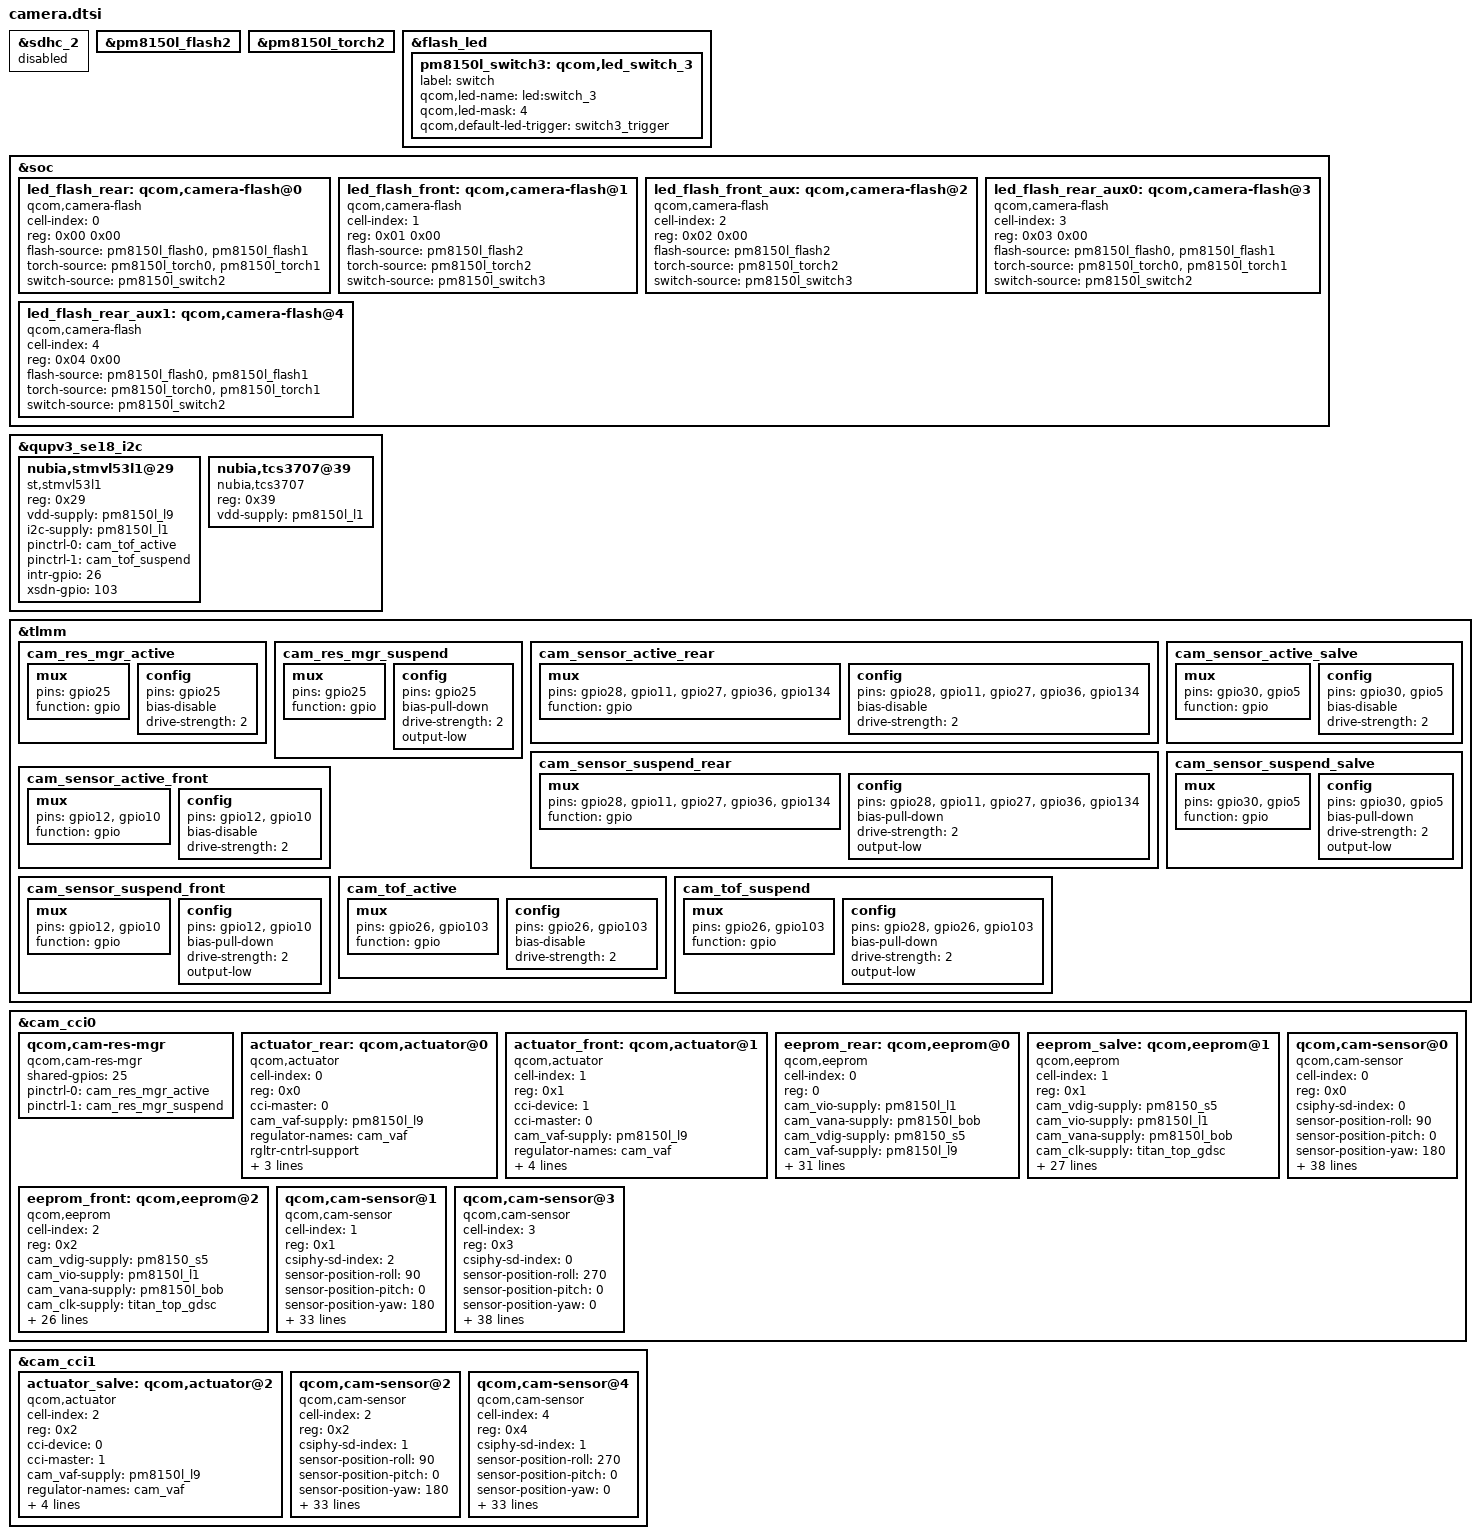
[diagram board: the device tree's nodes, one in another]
/*
 * Copyright (c) 2018, The Linux Foundation. All rights reserved.
 *
 * This program is free software; you can redistribute it and/or modify
 * it under the terms of the GNU General Public License version 2 and
 * only version 2 as published by the Free Software Foundation.
 *
 * This program is distributed in the hope that it will be useful,
 * but WITHOUT ANY WARRANTY; without even the implied warranty of
 * MERCHANTABILITY or FITNESS FOR A PARTICULAR PURPOSE.  See the
 * GNU General Public License for more details.
 */




&sdhc_2 {
	status = "disabled";
};
&pm8150l_flash2 {
    status = "ok";
};
&pm8150l_torch2 {
     status = "ok";
};
&flash_led {

	pm8150l_switch3: qcom,led_switch_3 {
		label = "switch";
		qcom,led-name = "led:switch_3";
		qcom,led-mask = <4>;
		qcom,default-led-trigger = "switch3_trigger";
	};
};
&soc {



	led_flash_rear: qcom,camera-flash@0 {
		cell-index = <0>;
		reg = <0x00 0x00>;
		compatible = "qcom,camera-flash";
		flash-source = <&pm8150l_flash0 &pm8150l_flash1>;
		torch-source = <&pm8150l_torch0 &pm8150l_torch1>;
		switch-source = <&pm8150l_switch2>;
		status = "ok";
	};
	led_flash_front: qcom,camera-flash@1 {
		cell-index = <1>;
		reg = <0x01 0x00>;
		compatible = "qcom,camera-flash";
		flash-source = <&pm8150l_flash2>;
		torch-source = <&pm8150l_torch2>;
		switch-source = <&pm8150l_switch3>;
		status = "ok";
	};
	led_flash_front_aux: qcom,camera-flash@2 {
		cell-index = <2>;
		reg = <0x02 0x00>;
		compatible = "qcom,camera-flash";
		flash-source = <&pm8150l_flash2>;
		torch-source = <&pm8150l_torch2>;
		switch-source = <&pm8150l_switch3>;
		status = "ok";
	};

	led_flash_rear_aux0: qcom,camera-flash@3 {
		cell-index = <3>;
		reg = <0x03 0x00>;
		compatible = "qcom,camera-flash";
		flash-source = <&pm8150l_flash0 &pm8150l_flash1>;
		torch-source = <&pm8150l_torch0 &pm8150l_torch1>;
		switch-source = <&pm8150l_switch2>;
		status = "ok";
	};

	led_flash_rear_aux1: qcom,camera-flash@4 {
		cell-index = <4>;
		reg = <0x04 0x00>;
		compatible = "qcom,camera-flash";
		flash-source = <&pm8150l_flash0 &pm8150l_flash1>;
		torch-source = <&pm8150l_torch0 &pm8150l_torch1>;
		switch-source = <&pm8150l_switch2>;
		status = "ok";
	};

};
	
&qupv3_se18_i2c {
        status = "ok";
	nubia,stmvl53l1@29 {
	        status = "okay";
		compatible = "st,stmvl53l1";
		reg = <0x29>;
		vdd-supply = <&pm8150l_l9>;
		i2c-supply = <&pm8150l_l1>;
		//interrupt-parent = <&tlmm>;
		//interrupts = <26 0x00>;
		pinctrl-names = "pmx_ts_active","pmx_ts_suspend";
		pinctrl-0 = <&cam_tof_active>;
		pinctrl-1 = <&cam_tof_suspend>;		
		intr-gpio = <26>;
		xsdn-gpio = <103>;
	};
	nubia,tcs3707@39{
		status = "okay";
		compatible = "nubia,tcs3707";
		reg = <0x39>;
		vdd-supply = <&pm8150l_l1>;
	};
};

&tlmm {
	/delete-node/ cam_sensor_front_active;
	/delete-node/ cam_sensor_front_suspend;
	/delete-node/ cam_sensor_rear_active;
	/delete-node/ cam_sensor_rear_suspend;

	cam_res_mgr_active: cam_res_mgr_active {
		/* AVDD_LDO*/
		mux {
			pins = "gpio25";
			function = "gpio";
		};

		config {
			pins = "gpio25";
			bias-disable; /* No PULL */
			drive-strength = <2>; /* 2 MA */
		};
	};

	cam_res_mgr_suspend: cam_res_mgr_suspend {
		/* AVDD_LDO */
		mux {
			pins = "gpio25";
			function = "gpio";
		};

		config {
			pins = "gpio25";
			bias-pull-down; /* PULL DOWN */
			drive-strength = <2>; /* 2 MA */
			output-low;
		};
	};

	cam_sensor_active_rear: cam_sensor_active_rear {
		/* RESET REAR */
		mux {
			pins = "gpio28", "gpio11", "gpio27", "gpio36","gpio134";
			function = "gpio";
		};

		config {
			pins = "gpio28", "gpio11", "gpio27", "gpio36","gpio134";
			bias-disable; /* No PULL */
			drive-strength = <2>; /* 2 MA */
		};
	};

	cam_sensor_suspend_rear: cam_sensor_suspend_rear {
		/* RESET REAR */
		mux {
			pins = "gpio28", "gpio11", "gpio27", "gpio36","gpio134";
			function = "gpio";
		};

		config {
			pins = "gpio28", "gpio11", "gpio27", "gpio36","gpio134";
			bias-pull-down; /* PULL DOWN */
			drive-strength = <2>; /* 2 MA */
			output-low;
		};
	};


	cam_sensor_active_front: cam_sensor_active_front {
		/* RESET FRONT */
		mux {
			pins = "gpio12", "gpio10";
			function = "gpio";
		};

		config {
			pins = "gpio12", "gpio10";
			bias-disable; /* No PULL */
			drive-strength = <2>; /* 2 MA */
		};
	};

	cam_sensor_suspend_front: cam_sensor_suspend_front {
		/* RESET FRONT */
		mux {
			pins = "gpio12", "gpio10";
			function = "gpio";
		};

		config {
			pins = "gpio12", "gpio10";
			bias-pull-down; /* PULL DOWN */
			drive-strength = <2>; /* 2 MA */
			output-low;
		};
	};
	cam_sensor_active_salve: cam_sensor_active_salve {
		/* RESET SALVE */
		mux {
			pins = "gpio30", "gpio5";
			function = "gpio";
		};

		config {
			pins = "gpio30", "gpio5";
			bias-disable; /* No PULL */
			drive-strength = <2>; /* 2 MA */
		};
	};

	cam_sensor_suspend_salve: cam_sensor_suspend_salve {
		/* RESET SALVE */
		mux {
			pins = "gpio30", "gpio5";
			function = "gpio";
		};

		config {
			pins = "gpio30", "gpio5";
			bias-pull-down; /* PULL DOWN */
			drive-strength = <2>; /* 2 MA */
			output-low;
		};
	};	

	cam_tof_active: cam_tof_active {
		/* TOF */
		mux {
			pins = "gpio26", "gpio103";
			function = "gpio";
		};

		config {
			pins = "gpio26", "gpio103";
			bias-disable; /* No PULL */
			drive-strength = <2>; /* 2 MA */
		};
	};

	cam_tof_suspend: cam_tof_suspend {
		/* TOF */
		mux {
			pins = "gpio26", "gpio103";
			function = "gpio";
		};

		config {
			pins = "gpio28", "gpio26", "gpio103";
			bias-pull-down; /* PULL DOWN */
			drive-strength = <2>; /* 2 MA */
			output-low;
		};
	};


};
&cam_cci0 {

	qcom,cam-res-mgr {
		compatible = "qcom,cam-res-mgr";
		status = "ok";
		shared-gpios = <25>;
		pinctrl-names = "cam_res_mgr_default", "cam_res_mgr_suspend";
		pinctrl-0 = <&cam_res_mgr_active>;
		pinctrl-1 = <&cam_res_mgr_suspend>;
	};

#if 0
	tcs37070: nubia,tcs3707@0{
		cell-index = <0>;
		reg = <0x39>;
		compatible = "nubia,tcs3707";
		cci-master = <0>;
		cci-device = <0>;
		vdd-supply = <&pm8150l_l1>;
	};	

	tof0: nubia,tof@0{
		cell-index = <0>;
		reg = <0x29>;
		compatible = "st,stmvl53l1";
		cci-master = <0>;
		cci-device = <0>;
		laser-supply = <&pm8150l_l9>;
		cci-supply = <&pm8150l_l1>;
		pinctrl-names = "cam_default", "cam_suspend";
		pinctrl-0 = <&cam_tof_active>;
		pinctrl-1 = <&cam_tof_suspend>;
		intr-gpio = <26>;
		xsdn-gpio = <103>;
	};	
#endif

	actuator_rear: qcom,actuator@0 {
		cell-index = <0>;
		reg = <0x0>;
		compatible = "qcom,actuator";
		cci-master = <0>;
		cam_vaf-supply = <&pm8150l_l9>;
		regulator-names = "cam_vaf";
		rgltr-cntrl-support;
		rgltr-min-voltage = <2800000>;
		rgltr-max-voltage = <2800000>;
		rgltr-load-current = <1200000>;
	};

	actuator_front: qcom,actuator@1 {
		cell-index = <1>;
		reg = <0x1>;
		compatible = "qcom,actuator";
		cci-device = <1>;
		cci-master = <0>;
		cam_vaf-supply = <&pm8150l_l9>;
		regulator-names = "cam_vaf";
		rgltr-cntrl-support;
		rgltr-min-voltage = <2800000>;
		rgltr-max-voltage = <2800000>;
		rgltr-load-current = <1200000>;
	};
	eeprom_rear: qcom,eeprom@0 {
		cell-index = <0>;
		reg = <0>;
		compatible = "qcom,eeprom";
		cam_vio-supply = <&pm8150l_l1>;
		cam_vana-supply = <&pm8150l_bob>;
		cam_vdig-supply = <&pm8150_s5>;
		cam_vaf-supply = <&pm8150l_l9>;
		cam_clk-supply = <&titan_top_gdsc>;
		regulator-names = "cam_vio", "cam_vana", "cam_vdig", "cam_vaf",
			"cam_clk";
		rgltr-cntrl-support;
		rgltr-min-voltage = <0 3300000 1950000 2800000 0>;
		rgltr-max-voltage = <0 3300000 1950000 2800000 0>;
		rgltr-load-current = <0 80000 1200000 1200000 0>;
		gpio-no-mux = <0>;
		pinctrl-names = "cam_default", "cam_suspend";
		pinctrl-0 = <&cam_sensor_mclk0_active
				&cam_sensor_active_rear>;
		pinctrl-1 = <&cam_sensor_mclk0_suspend
				&cam_sensor_suspend_rear>;
		gpios = <&tlmm 13 0>,
			<&tlmm 28 0>,
			<&tlmm 11 0>,
			<&tlmm 27 0>,
			<&tlmm 134 0>,
			<&tlmm 36 0>;
		gpio-reset = <1>;
		gpio-vana = <2>;
		gpio-vdig = <3>;
		gpio-custom1 = <4>;
		gpio-custom2 = <5>;
		gpio-req-tbl-num = <0 1 2 3 4 5>;
		gpio-req-tbl-flags = <1 0 0 0 0 0>;
		gpio-req-tbl-label = "CAMIF_MCLK0",
					"CAM_RESET0",
					"CAM_VANA0",
					"CAM_VDIG0",
					"CAM_CUSTOM1",
					"CAM_CUSTOM2";
		sensor-position = <0>;
		sensor-mode = <0>;
		cci-device = <0>;
		cci-master = <0>;
		status = "ok";
		clocks = <&clock_camcc CAM_CC_MCLK0_CLK>;
		clock-names = "cam_clk";
		clock-cntl-level = "turbo";
		clock-rates = <19200000>;


	};

	eeprom_salve: qcom,eeprom@1 {
		cell-index = <1>;
		reg = <0x1>;
		compatible = "qcom,eeprom";
		cam_vdig-supply = <&pm8150_s5>;
		cam_vio-supply = <&pm8150l_l1>;
		cam_vana-supply = <&pm8150l_bob>;
		cam_clk-supply = <&titan_top_gdsc>;
		regulator-names = "cam_vio", "cam_vana", "cam_vdig",
			"cam_clk";
		rgltr-cntrl-support;
		pwm-switch;
		rgltr-min-voltage = <0 3300000 1950000 0>;
		rgltr-max-voltage = <0 3300000 1950000 0>;
		rgltr-load-current = <0 80000 1200000 0>;
		gpio-no-mux = <0>;
		pinctrl-names = "cam_default", "cam_suspend";
		pinctrl-0 = <&cam_sensor_mclk1_active
				 &cam_sensor_active_salve>;
		pinctrl-1 = <&cam_sensor_mclk1_suspend
				 &cam_sensor_suspend_salve>;
		gpios = <&tlmm 14 0>,
			<&tlmm 30 0>,
			<&tlmm 25 0>,
			<&tlmm 5  0>;
		gpio-reset = <1>;
		gpio-vana = <2>;
		gpio-vdig = <3>;
		gpio-req-tbl-num = <0 1 2 3>;
		gpio-req-tbl-flags = <1 0 0 0>;
		gpio-req-tbl-label = "CAMIF_MCLK3",
					"CAM_RESET3",
					"CAM_VANA3",
					"CAM_VDIG3";
		sensor-position = <0>;
		sensor-mode = <0>;
		cci-device = <0>;
		cci-master = <1>;
		status = "ok";
		clocks = <&clock_camcc CAM_CC_MCLK1_CLK>;
		clock-names = "cam_clk";
		clock-cntl-level = "turbo";
		clock-rates = <19200000>;
	};
	eeprom_front: qcom,eeprom@2 {
		cell-index = <2>;
		reg = <0x2>;
		compatible = "qcom,eeprom";
		//cam_bob-supply = <&pm8150l_bob>;
		cam_vdig-supply = <&pm8150_s5>;
		cam_vio-supply = <&pm8150l_l1>;
		cam_vana-supply = <&pm8150l_bob>;
		cam_clk-supply = <&titan_top_gdsc>;
		regulator-names = "cam_vio", "cam_vana", "cam_vdig",
			"cam_clk";
		rgltr-cntrl-support;
		pwm-switch;
		rgltr-min-voltage = <0 3300000 1950000 0>;
		rgltr-max-voltage = <0 3300000 1950000 0>;
		rgltr-load-current = <0 80000 1200000 0>;
		gpio-no-mux = <0>;
		pinctrl-names = "cam_default", "cam_suspend";
		pinctrl-0 = <&cam_sensor_mclk2_active
				 &cam_sensor_active_front>;
		pinctrl-1 = <&cam_sensor_mclk2_suspend
				 &cam_sensor_suspend_front>;
		gpios = <&tlmm 15 0>,
			<&tlmm 12 0>,
			<&tlmm 25 0>,
			<&tlmm 10 0>;
		gpio-reset = <1>;
		gpio-vana = <2>;
		gpio-vdig = <3>;
		gpio-req-tbl-num = <0 1 2 3>;
		gpio-req-tbl-flags = <1 0 0 0>;
		gpio-req-tbl-label = "CAMIF_MCLK2",
					"CAM_RESET2",
					"CAM_VANA2",
					"CAM_VDIG2";
		sensor-mode = <0>;
		cci-device = <1>;
		cci-master = <0>;
		status = "ok";
		clocks = <&clock_camcc CAM_CC_MCLK2_CLK>;
		clock-names = "cam_clk";
		clock-cntl-level = "turbo";
		clock-rates = <19200000>;
	};
	qcom,cam-sensor@0 {
		cell-index = <0>;
		compatible = "qcom,cam-sensor";
		reg = <0x0>;
		csiphy-sd-index = <0>;
		sensor-position-roll = <90>;
		sensor-position-pitch = <0>;
		sensor-position-yaw = <180>;
		actuator-src = <&actuator_rear>;
		eeprom-src = <&eeprom_rear>;
		led-flash-src = <&led_flash_rear>;
		cam_vio-supply = <&pm8150l_l1>;
		cam_vana-supply = <&pm8150l_bob>;
		cam_vdig-supply = <&pm8150_s5>;
		cam_vaf-supply = <&pm8150l_l9>;
		cam_clk-supply = <&titan_top_gdsc>;
		regulator-names = "cam_vio", "cam_vana", "cam_vdig", "cam_vaf",
			"cam_clk";
		rgltr-cntrl-support;
		pwm-switch;
		rgltr-min-voltage = <0 3300000 1950000 2800000 0>;
		rgltr-max-voltage = <0 3300000 1950000 2800000 0>;
		rgltr-load-current = <0 80000 1200000 1200000 0>;
		gpio-no-mux = <0>;
		pinctrl-names = "cam_default", "cam_suspend";
		pinctrl-0 = <&cam_sensor_mclk0_active
				&cam_sensor_active_rear>;
		pinctrl-1 = <&cam_sensor_mclk0_suspend
				&cam_sensor_suspend_rear>;
		gpios = <&tlmm 13 0>,
			<&tlmm 28 0>,
			<&tlmm 11 0>,
			<&tlmm 27 0>,
			<&tlmm 134 0>,
			<&tlmm 36 0>;
		gpio-reset = <1>;
		gpio-vana = <2>;
		gpio-vdig = <3>;
		gpio-custom1 = <4>;
		gpio-custom2 = <5>;
		gpio-req-tbl-num = <0 1 2 3 4 5>;
		gpio-req-tbl-flags = <1 0 0 0 0 0>;
		gpio-req-tbl-label = "CAMIF_MCLK0",
					"CAM_RESET0",
					"CAM_VANA0",
					"CAM_VDIG0",
					"CAM_CUSTOM1",
					"CAM_CUSTOM2";
		sensor-mode = <0>;
		cci-device = <0>;
		cci-master = <0>;
		status = "ok";
		clocks = <&clock_camcc CAM_CC_MCLK0_CLK>;
		clock-names = "cam_clk";
		clock-cntl-level = "turbo";
		clock-rates = <19200000>;
	};


	qcom,cam-sensor@1 {
		cell-index = <1>;
		compatible = "qcom,cam-sensor";
		reg = <0x1>;
		csiphy-sd-index = <2>;
		sensor-position-roll = <90>;
		sensor-position-pitch = <0>;
		sensor-position-yaw = <180>;
		eeprom-src = <&eeprom_front>;
		actuator-src = <&actuator_front>;
		led-flash-src = <&led_flash_rear_aux0>;
		//cam_bob-supply = <&pm8150l_bob>;
		cam_vdig-supply = <&pm8150_s5>;
		cam_vio-supply = <&pm8150l_l1>;
		cam_vana-supply = <&pm8150l_bob>;
		cam_clk-supply = <&titan_top_gdsc>;
		regulator-names = "cam_vio", "cam_vana", "cam_vdig",
			"cam_clk";
		rgltr-cntrl-support;
		pwm-switch;
		rgltr-min-voltage = <0 3300000 1950000 0>;
		rgltr-max-voltage = <0 3300000 1950000 0>;
		rgltr-load-current = <0 80000 1200000 0>;
		gpio-no-mux = <0>;
		pinctrl-names = "cam_default", "cam_suspend";
		pinctrl-0 = <&cam_sensor_mclk2_active
				 &cam_sensor_active_front>;
		pinctrl-1 = <&cam_sensor_mclk2_suspend
				 &cam_sensor_suspend_front>;
		gpios = <&tlmm 15 0>,
			<&tlmm 12 0>,
			<&tlmm 25 0>,
			<&tlmm 10 0>;
		gpio-reset = <1>;
		gpio-vana = <2>;
		gpio-vdig = <3>;
		gpio-req-tbl-num = <0 1 2 3>;
		gpio-req-tbl-flags = <1 0 0 0>;
		gpio-req-tbl-label = "CAMIF_MCLK2",
					"CAM_RESET2",
					"CAM_VANA2",
					"CAM_VDIG2";
					
		sensor-mode = <0>;
		cci-device = <1>;
		cci-master = <0>;
		status = "ok";
		clocks = <&clock_camcc CAM_CC_MCLK2_CLK>;
		clock-names = "cam_clk";
		clock-cntl-level = "turbo";
		clock-rates = <19200000>;
	};
	qcom,cam-sensor@3 {
		cell-index = <3>;
		compatible = "qcom,cam-sensor";
		reg = <0x3>;
		csiphy-sd-index = <0>;
		sensor-position-roll = <270>;
		sensor-position-pitch = <0>;
		sensor-position-yaw = <0>;
		actuator-src = <&actuator_rear>;
		eeprom-src = <&eeprom_rear>;
		led-flash-src = <&led_flash_front>;
		cam_vio-supply = <&pm8150l_l1>;
		cam_vana-supply = <&pm8150l_bob>;
		cam_vdig-supply = <&pm8150_s5>;
		cam_vaf-supply = <&pm8150l_l9>;
		cam_clk-supply = <&titan_top_gdsc>;
		regulator-names = "cam_vio", "cam_vana", "cam_vdig", "cam_vaf",
			"cam_clk";
		rgltr-cntrl-support;
		pwm-switch;
		rgltr-min-voltage = <0 3300000 1950000 2800000 0>;
		rgltr-max-voltage = <0 3300000 1950000 2800000 0>;
		rgltr-load-current = <0 80000 1200000 1200000 0>;
		gpio-no-mux = <0>;
		pinctrl-names = "cam_default", "cam_suspend";
		pinctrl-0 = <&cam_sensor_mclk0_active
				&cam_sensor_active_rear>;
		pinctrl-1 = <&cam_sensor_mclk0_suspend
				&cam_sensor_suspend_rear>;
		gpios = <&tlmm 13 0>,
			<&tlmm 28 0>,
			<&tlmm 11 0>,
			<&tlmm 27 0>,
			<&tlmm 134 0>,
			<&tlmm 36 0>;
		gpio-reset = <1>;
		gpio-vana = <2>;
		gpio-vdig = <3>;
		gpio-custom1 = <4>;
		gpio-custom2 = <5>;
		gpio-req-tbl-num = <0 1 2 3 4 5>;
		gpio-req-tbl-flags = <1 0 0 0 0 0>;
		gpio-req-tbl-label = "CAMIF_MCLK0",
					"CAM_RESET0",
					"CAM_VANA0",
					"CAM_VDIG0",
					"CAM_CUSTOM1",
					"CAM_CUSTOM2";
		sensor-mode = <0>;
		cci-device = <0>;
		cci-master = <0>;
		status = "ok";
		clocks = <&clock_camcc CAM_CC_MCLK0_CLK>;
		clock-names = "cam_clk";
		clock-cntl-level = "turbo";
		clock-rates = <19200000>;
	};
#if 0
	qcom,cam-sensor@4 {
		cell-index = <4>;
		compatible = "qcom,cam-sensor";
		reg = <0x4>;
		csiphy-sd-index = <2>;
		sensor-position-roll = <270>;
		sensor-position-pitch = <0>;
		sensor-position-yaw = <0>;
		//eeprom-src = <&eeprom_front>;
		actuator-src = <&actuator_front>;
		//cam_bob-supply = <&pm8150l_bob>;
		cam_vdig-supply = <&pm8150_s5>;
		cam_vio-supply = <&pm8150l_l1>;
		cam_vana-supply = <&pm8150l_bob>;
		cam_clk-supply = <&titan_top_gdsc>;
		regulator-names = "cam_vio", "cam_vana", "cam_vdig",
			"cam_clk";
		rgltr-cntrl-support;
		pwm-switch;
		rgltr-min-voltage = <0 3300000 1950000 0>;
		rgltr-max-voltage = <0 3300000 1950000 0>;
		rgltr-load-current = <0 80000 1200000 0>;
		gpio-no-mux = <0>;
		pinctrl-names = "cam_default", "cam_suspend";
		pinctrl-0 = <&cam_sensor_mclk2_active
				 &cam_sensor_active_front>;
		pinctrl-1 = <&cam_sensor_mclk2_suspend
				 &cam_sensor_suspend_front>;
		gpios = <&tlmm 15 0>,
			<&tlmm 12 0>,
			<&tlmm 25 0>,
			<&tlmm 10 0>;
		gpio-reset = <1>;
		gpio-vana = <2>;
		gpio-vdig = <3>;
		gpio-req-tbl-num = <0 1 2 3>;
		gpio-req-tbl-flags = <1 0 0 0>;
		gpio-req-tbl-label = "CAMIF_MCLK2",
					"CAM_RESET2",
					"CAM_VANA2",
					"CAM_VDIG2";
					
		sensor-mode = <0>;
		cci-device = <1>;
		cci-master = <0>;
		status = "ok";
		clocks = <&clock_camcc CAM_CC_MCLK2_CLK>;
		clock-names = "cam_clk";
		clock-cntl-level = "turbo";
		clock-rates = <19200000>;
	};
#endif
};
&cam_cci1 {
	actuator_salve: qcom,actuator@2 {
		cell-index = <2>;
		reg = <0x2>;
		compatible = "qcom,actuator";
		cci-device = <0>;
		cci-master = <1>;
		cam_vaf-supply = <&pm8150l_l9>;
		regulator-names = "cam_vaf";
		rgltr-cntrl-support;
		rgltr-min-voltage = <2800000>;
		rgltr-max-voltage = <2800000>;
		rgltr-load-current = <1200000>;
	};

	qcom,cam-sensor@2 {
		cell-index = <2>;
		compatible = "qcom,cam-sensor";
		reg = <0x2>;
		csiphy-sd-index = <1>;
		sensor-position-roll = <90>;
		sensor-position-pitch = <0>;
		sensor-position-yaw = <180>;
		eeprom-src = <&eeprom_salve>;
		actuator-src = <&actuator_salve>;
		led-flash-src = <&led_flash_rear_aux1>;
		//cam_bob-supply = <&pm8150l_bob>;
		cam_vdig-supply = <&pm8150_s5>;
		cam_vio-supply = <&pm8150l_l1>;
		cam_vana-supply = <&pm8150l_bob>;
		cam_clk-supply = <&titan_top_gdsc>;
		regulator-names = "cam_vio", "cam_vana", "cam_vdig",
			"cam_clk";
		rgltr-cntrl-support;
		pwm-switch;
		rgltr-min-voltage = <0 3300000 1950000 0>;
		rgltr-max-voltage = <0 3300000 1950000 0>;
		rgltr-load-current = <0 80000 1200000 0>;
		gpio-no-mux = <0>;
		pinctrl-names = "cam_default", "cam_suspend";
		pinctrl-0 = <&cam_sensor_mclk1_active
				 &cam_sensor_active_salve>;
		pinctrl-1 = <&cam_sensor_mclk1_suspend
				 &cam_sensor_suspend_salve>;
		gpios = <&tlmm 14 0>,
			<&tlmm 30 0>,
			<&tlmm 25 0>,
			<&tlmm 5  0>;
		gpio-reset = <1>;
		gpio-vana = <2>;
		gpio-vdig = <3>;
		gpio-req-tbl-num = <0 1 2 3>;
		gpio-req-tbl-flags = <1 0 0 0>;
		gpio-req-tbl-label = "CAMIF_MCLK3",
					"CAM_RESET3",
					"CAM_VANA3",
					"CAM_VDIG3";
					
		sensor-mode = <0>;
		cci-device = <0>;
		cci-master = <1>;
		status = "ok";
		clocks = <&clock_camcc CAM_CC_MCLK1_CLK>;
		clock-names = "cam_clk";
		clock-cntl-level = "turbo";
		clock-rates = <19200000>;
	};

	qcom,cam-sensor@4 {
		cell-index = <4>;
		compatible = "qcom,cam-sensor";
		reg = <0x4>;
		csiphy-sd-index = <1>;
		sensor-position-roll = <270>;
		sensor-position-pitch = <0>;
		sensor-position-yaw = <0>;
		eeprom-src = <&eeprom_salve>;
		actuator-src = <&actuator_salve>;
		led-flash-src = <&led_flash_front_aux>;
		//cam_bob-supply = <&pm8150l_bob>;
		cam_vdig-supply = <&pm8150_s5>;
		cam_vio-supply = <&pm8150l_l1>;
		cam_vana-supply = <&pm8150l_bob>;
		cam_clk-supply = <&titan_top_gdsc>;
		regulator-names = "cam_vio", "cam_vana", "cam_vdig",
			"cam_clk";
		rgltr-cntrl-support;
		pwm-switch;
		rgltr-min-voltage = <0 3300000 1950000 0>;
		rgltr-max-voltage = <0 3300000 1950000 0>;
		rgltr-load-current = <0 80000 1200000 0>;
		gpio-no-mux = <0>;
		pinctrl-names = "cam_default", "cam_suspend";
		pinctrl-0 = <&cam_sensor_mclk1_active
				 &cam_sensor_active_salve>;
		pinctrl-1 = <&cam_sensor_mclk1_suspend
				 &cam_sensor_suspend_salve>;
		gpios = <&tlmm 14 0>,
			<&tlmm 30 0>,
			<&tlmm 25 0>,
			<&tlmm 5  0>;
		gpio-reset = <1>;
		gpio-vana = <2>;
		gpio-vdig = <3>;
		gpio-req-tbl-num = <0 1 2 3>;
		gpio-req-tbl-flags = <1 0 0 0>;
		gpio-req-tbl-label = "CAMIF_MCLK3",
					"CAM_RESET3",
					"CAM_VANA3",
					"CAM_VDIG3";
					
		sensor-mode = <0>;
		cci-device = <0>;
		cci-master = <1>;
		status = "ok";
		clocks = <&clock_camcc CAM_CC_MCLK1_CLK>;
		clock-names = "cam_clk";
		clock-cntl-level = "turbo";
		clock-rates = <19200000>;
	};	

};


